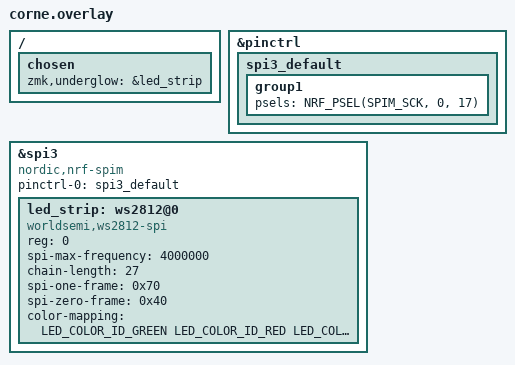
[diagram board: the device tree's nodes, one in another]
// User overlay for the official ZMK `corne` shield.
// Placed in `config/<shield>.overlay` so Zephyr picks it up automatically
// for both halves (corne_left and corne_right).

&pinctrl {
    spi3_default: spi3_default {
        group1 {
            // Data line for the WS2812 LED strip on Corne v3 (P0.17 / pro_micro D16).
            psels = <NRF_PSEL(SPIM_SCK, 0, 17)>;
        };
    };
};

&spi3 {
    compatible = "nordic,nrf-spim";
    status = "okay";
    pinctrl-0 = <&spi3_default>;
    pinctrl-names = "default";

    led_strip: ws2812@0 {
        compatible = "worldsemi,ws2812-spi";

        /* SPI */
        reg = <0>;
        spi-max-frequency = <4000000>;

        /* WS2812: 21 per-key + 6 underglow per half on Corne v3. */
        chain-length = <27>;
        spi-one-frame = <0x70>;
        spi-zero-frame = <0x40>;
        color-mapping = <LED_COLOR_ID_GREEN LED_COLOR_ID_RED LED_COLOR_ID_BLUE>;
    };
};

/ {
    chosen {
        zmk,underglow = &led_strip;
    };
};
